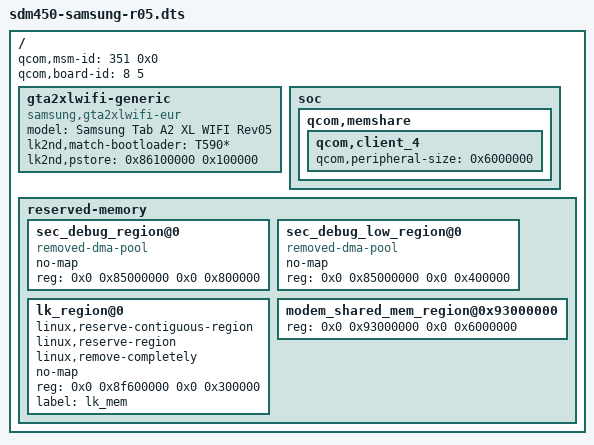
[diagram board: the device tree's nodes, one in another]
// SPDX-License-Identifier: GPL-2.0-only

/dts-v1/;

/include/ "msm8953.dtsi"

/ {
	// This is used by the bootloader to find the correct DTB
	qcom,msm-id = <351 0x0>;
	qcom,board-id = <8 5>;
	
	gta2xlwifi-generic {
		model = "Samsung Tab A2 XL WIFI Rev05";
		compatible = "samsung,gta2xlwifi-eur", "qcom,sdm450", "qcom,msm8953", "lk2nd,device";
		lk2nd,match-bootloader = "T590*";
		lk2nd,pstore = <0x86100000 0x100000>;
	};
	
	// Bootloader won't continue if it can't delete some nodes from below
	soc {
		#address-cells = <1>;
		#size-cells = <1>;
		ranges = <0x0 0x0 0x0 0xffffffff>;

		qcom,memshare {
			qcom,client_4 {
				qcom,peripheral-size = <0x6000000>;
			};
		};
	};

	reserved-memory {
		#address-cells = <2>;
		#size-cells = <2>;
		ranges;

		sec_debug_region@0 {
			compatible = "removed-dma-pool";
			no-map;
			reg = <0x0 0x85000000 0x0 0x800000>;
		};

		sec_debug_low_region@0 {
			compatible = "removed-dma-pool";
			no-map;
			reg = <0x0 0x85000000 0x0 0x400000>;
		};

		lk_region@0 {
			linux,reserve-contiguous-region;
			linux,reserve-region;
			linux,remove-completely;
			no-map;
			reg = <0x0 0x8f600000 0x0 0x300000>;
			label = "lk_mem";
		};

		modem_shared_mem_region@0x93000000 {
			reg = <0x0 0x93000000 0x0 0x6000000>;
		};

	};
};
